# AON_SYSCTL register map
Vendor: Texas Instruments
Peripheral module from a debugger description file (folder CC26x0R2F).
Registers are 32-bit, access per field, reset 0x0 unless marked. A register's access mark holds for its fields unless they carry their own. Offsets are as the file gives them; lines under a group give offsets from that group; [hi:lo] are bit positions; {n}, {i} and the like mark numbered series; 'fields as' and 'values as' point back to an identical list; <NAME> marks a mode.

## AON_SYSCTL — This component controls AON_SYSCTL, which is the device's system controller. Note: This module is only supporting 32 bit ReadWrite access from MCU
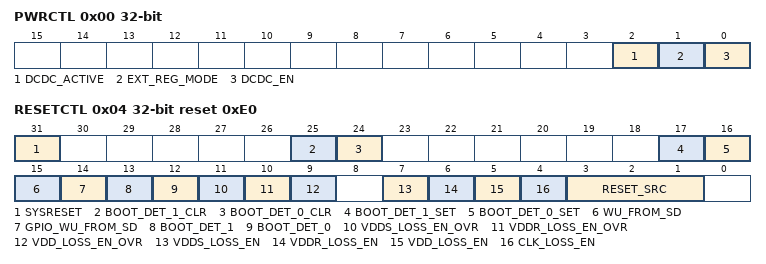
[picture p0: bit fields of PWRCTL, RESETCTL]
0x00 PWRCTL — Power Management This register controls bitfields for setting low level power management features such as selection of regulator for VDDR supply and control of IO ring where certain segments can be enabled / disabled.
  [2] DCDC_ACTIVE rw — Select to use DCDC regulator for VDDR in active mode 0: Use GLDO for regulation of VDDRin active mode. 1: Use DCDC for regulation of VDDRin active mode.
  [1] EXT_REG_MODE ro — Status of source for VDDRsupply: 0: DCDC/GLDO are generating VDDR 1: DCDC/GLDO are bypassed, external regulator supplies VDDR
  [0] DCDC_EN rw — Select to use DCDC regulator during recharge of VDDR 0: Use GLDO for recharge of VDDR 1: Use DCDC for recharge of VDDR Note: This bitfield should be set to the same as DCDC_ACTIVE
0x04 RESETCTL reset 0xE0 — Reset Management This register contains bitfields releated to system reset such as reset source and reset request and control of brown out resets.
  [31] SYSRESET wo — Cold reset register. Writing 1 to this bitfield will reset the entire chip and cause boot code to run again. 0: No effect 1: Generate system reset. Appears as SYSRESET in RESET_SRC.
  [25] BOOT_DET_1_CLR rw — Internal. Only to be used through TI provided API.
  [24] BOOT_DET_0_CLR rw — Internal. Only to be used through TI provided API.
  [17] BOOT_DET_1_SET rw — Internal. Only to be used through TI provided API.
  [16] BOOT_DET_0_SET rw — Internal. Only to be used through TI provided API.
  [15] WU_FROM_SD ro — A Wakeup from SHUTDOWN on an IO event has occurred, or a wakeup from SHUTDOWN has occurred as a result of the debugger being attached.. (TCK pin being forced low) Please refer to [IOC:IOCFGn,.WU_CFG] for configuring the IO's as wakeup sources. 0: Wakeup occurred from cold reset or brown out as seen in RESET_SRC 1: A wakeup has occurred from SHUTDOWN Note: This flag can not be cleared and will therefor remain valid untill poweroff/reset
  [14] GPIO_WU_FROM_SD ro — A wakeup from SHUTDOWN on an IO event has occurred Please refer to [IOC:IOCFGn,.WU_CFG] for configuring the IO's as wakeup sources. 0: The wakeup did not occur from SHUTDOWN on an IO event 1: A wakeup from SHUTDOWN occurred from an IO event The case where WU_FROM_SD is asserted but this bitfield is not asserted will only occur in a debug session. The boot code will not proceed with wakeup from SHUTDOWN procedure until this bitfield is asserted as well. Note: This flag can not be cleared and will therefor remain valid untill poweroff/reset
  [13] BOOT_DET_1 ro — Internal. Only to be used through TI provided API.
  [12] BOOT_DET_0 ro — Internal. Only to be used through TI provided API.
  [11] VDDS_LOSS_EN_OVR rw — Override of VDDS_LOSS_EN 0: Brown out detect of VDDS is ignored, unless VDDS_LOSS_EN=1 1: Brown out detect of VDDS generates system reset (regardless of VDDS_LOSS_EN) This bit can be locked
  [10] VDDR_LOSS_EN_OVR rw — Override of VDDR_LOSS_EN 0: Brown out detect of VDDR is ignored, unless VDDR_LOSS_EN=1 1: Brown out detect of VDDR generates system reset (regardless of VDDR_LOSS_EN) This bit can be locked
  [9] VDD_LOSS_EN_OVR rw — Override of VDD_LOSS_EN 0: Brown out detect of VDD is ignored, unless VDD_LOSS_EN=1 1: Brown out detect of VDD generates system reset (regardless of VDD_LOSS_EN) This bit can be locked
  [7] VDDS_LOSS_EN rw — Controls reset generation in case VDDS is lost 0: Brown out detect of VDDS is ignored, unless VDDS_LOSS_EN_OVR=1 1: Brown out detect of VDDS generates system reset
  [6] VDDR_LOSS_EN rw — Controls reset generation in case VDDR is lost 0: Brown out detect of VDDR is ignored, unless VDDR_LOSS_EN_OVR=1 1: Brown out detect of VDDR generates system reset
  [5] VDD_LOSS_EN rw — Controls reset generation in case VDD is lost 0: Brown out detect of VDD is ignored, unless VDD_LOSS_EN_OVR=1 1: Brown out detect of VDD generates system reset
  [4] CLK_LOSS_EN rw — Controls reset generation in case SCLK_LF is lost. (provided that clock loss detection is enabled by DDI_0_OSC:CTL0.CLK_LOSS_EN) Note: Clock loss reset generation must be disabled before SCLK_LF clock source is changed in DDI_0_OSC:CTL0.SCLK_LF_SRC_SEL and remain disabled untill the change is confirmed in DDI_0_OSC:STAT0.SCLK_LF_SRC. Failure to do so may result in a spurious system reset. Clock loss reset generation can be disabled through this bitfield or by clearing DDI_0_OSC:CTL0.CLK_LOSS_EN 0: Clock loss is ignored 1: Clock loss generates system reset
  [3:1] RESET_SRC ro — Shows the source of the last system reset: Occurrence of one of the reset sources may trigger several other reset sources as essential parts of the system are undergoing reset. This field will report the root cause of the reset (not the other resets that are consequence of the system reset). To support this feature the actual register is not captured before the reset source being released. If a new reset source is triggered, in a window of four 32 kHz periods after the previous has been released, this register may indicate Power on reset as source.
    7=WARMRESET (Software reset via PRCM warm reset request); 6=SYSRESET (Software reset via SYSRESET register); 5=CLK_LOSS (Clock loss detect); 4=VDDR_LOSS (Brown out detect on VDDR); 3=VDD_LOSS (Brown out detect on VDD); 2=VDDS_LOSS (Brown out detect on VDDS); 1=PIN_RESET (Reset pin); 0=PWR_ON (Power on reset)
0x08 SLEEPCTL — Sleep Mode This register is used to unfreeze the IO pad ring after waking up from SHUTDOWN
  [0] IO_PAD_SLEEP_DIS rw — Controls the I/O pad sleep mode. The boot code will set this bitfield automatically unless waking up from a SHUTDOWN ( RESETCTL.WU_FROM_SD is set ). 0: I/O pad sleep mode is enabled, ie all pads are latched and can not toggle. 1: I/O pad sleep mode is disabled Application software may want to reconfigure the state for all IO's before setting this bitfield upon waking up from a SHUTDOWN.
